# ESP32S31_RADIO register map
Vendor: Espressif; Series: ESP32-S31; File version: 3.52
Registers are 32-bit, read-write, no defined reset value unless marked. A register's access mark holds for its fields unless they carry their own. Offsets are from the block's base; [hi:lo] are bit positions.

## HP_SYS_CLKRST_RADIO — Route-owned high-power system clock/reset words shared by the reviewed Wi-Fi, Bluetooth and IEEE 802.15.4 lifecycles. Unrelated HP_SYS_CLKRST words remain platform-owned.
Base 0x20587000
0x40 MODEM_CTRL0 reset 0x1 — Modem control/register-bus clock gate.
  [0] MODEM_CLK_EN — Modem control/register-bus clock enable.
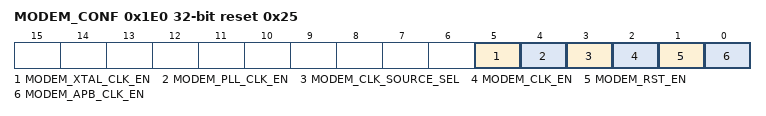
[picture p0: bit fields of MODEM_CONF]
0x1E0 MODEM_CONF reset 0x25 — Modem APB, reset and source-clock configuration.
  [5] MODEM_XTAL_CLK_EN — Modem crystal clock enable.
  [4] MODEM_PLL_CLK_EN — Modem PLL clock enable.
  [3] MODEM_CLK_SOURCE_SEL — Modem source-clock selector.
  [2] MODEM_CLK_EN — Modem source-clock enable.
  [1] MODEM_RST_EN — Modem subsystem reset assertion.
  [0] MODEM_APB_CLK_EN — Modem APB clock enable.

## MODEM_LPCON_SHARED_CLOCK — Role-neutral MODEM_LPCON clock-map, gate and low-power selector registers shared by the exclusive Wi-Fi, Bluetooth and IEEE 802.15.4 routes.
Base 0x2010F000
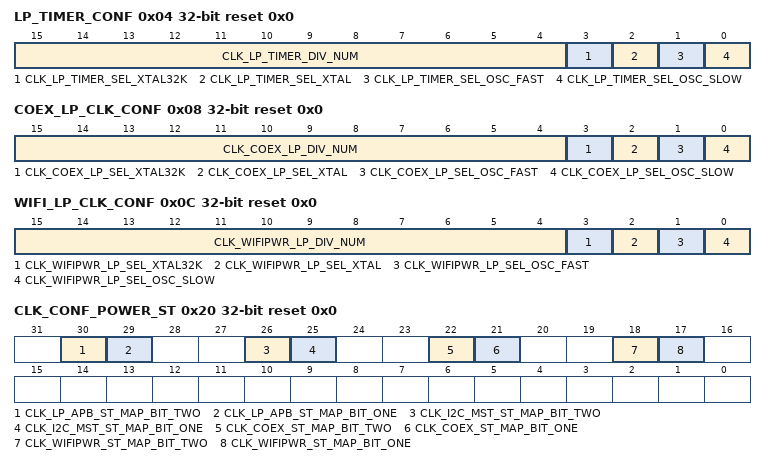
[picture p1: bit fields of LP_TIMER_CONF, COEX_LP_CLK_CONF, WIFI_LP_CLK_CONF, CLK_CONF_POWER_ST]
0x04 LP_TIMER_CONF reset 0x0 — Bluetooth low-power timer source selector and twelve-bit divider.
  [15:4] CLK_LP_TIMER_DIV_NUM — Twelve-bit low-power timer divider image.
  [3] CLK_LP_TIMER_SEL_XTAL32K — Select the 32 kHz crystal clock.
  [2] CLK_LP_TIMER_SEL_XTAL — Select the crystal clock.
  [1] CLK_LP_TIMER_SEL_OSC_FAST — Select the fast oscillator.
  [0] CLK_LP_TIMER_SEL_OSC_SLOW — Select the slow oscillator.
0x08 COEX_LP_CLK_CONF reset 0x0 — Coexistence low-power source selector and twelve-bit divider sampled by the coexistence time conversion.
  [15:4] CLK_COEX_LP_DIV_NUM — Twelve-bit coexistence low-power clock divider image.
  [3] CLK_COEX_LP_SEL_XTAL32K — Select the 32 kHz crystal clock.
  [2] CLK_COEX_LP_SEL_XTAL — Select the crystal clock.
  [1] CLK_COEX_LP_SEL_OSC_FAST — Select the fast oscillator.
  [0] CLK_COEX_LP_SEL_OSC_SLOW — Select the slow oscillator.
0x0C WIFI_LP_CLK_CONF reset 0x0 — Wi-Fi power-domain low-power source selector and twelve-bit divider.
  [15:4] CLK_WIFIPWR_LP_DIV_NUM — Twelve-bit Wi-Fi power-domain low-power divider image.
  [3] CLK_WIFIPWR_LP_SEL_XTAL32K — Select the modem 32 kHz clock chosen by MODEM_32K_CLK_CONF.
  [2] CLK_WIFIPWR_LP_SEL_XTAL — Select the main crystal clock.
  [1] CLK_WIFIPWR_LP_SEL_OSC_FAST — Select the fast oscillator.
  [0] CLK_WIFIPWR_LP_SEL_OSC_SLOW — Select the slow oscillator.
0x14 MODEM_32K_CLK_CONF reset 0x0 — Source of the modem 32 kHz clock selected by the low-power XTAL32K selectors.
  [1:0] CLK_MODEM_32K_SEL — Modem 32 kHz source: zero is the 32 kHz crystal, one the RC32K oscillator and two the external 32 kHz clock.
0x20 CLK_CONF_POWER_ST reset 0x0 — Four shared clock power-state map fields programmed with the reviewed active-state image.
  [30] CLK_LP_APB_ST_MAP_BIT_TWO — Project-assigned name. Bit two of the low-power APB clock state map, set by the reviewed shared active-state initialization.
  [29] CLK_LP_APB_ST_MAP_BIT_ONE — Project-assigned name. Bit one of the low-power APB clock state map, set by the reviewed shared active-state initialization.
  [26] CLK_I2C_MST_ST_MAP_BIT_TWO — Project-assigned name. Bit two of the PHY-I2C-master clock state map, set by the reviewed shared active-state initialization.
  [25] CLK_I2C_MST_ST_MAP_BIT_ONE — Project-assigned name. Bit one of the PHY-I2C-master clock state map, set by the reviewed shared active-state initialization.
  [22] CLK_COEX_ST_MAP_BIT_TWO — Project-assigned name. Bit two of the coexistence clock state map, set by the reviewed shared active-state initialization.
  [21] CLK_COEX_ST_MAP_BIT_ONE — Project-assigned name. Bit one of the coexistence clock state map, set by the reviewed shared active-state initialization.
  [18] CLK_WIFIPWR_ST_MAP_BIT_TWO — Project-assigned name. Bit two of the Wi-Fi-power clock state map, set by the reviewed shared active-state initialization.
  [17] CLK_WIFIPWR_ST_MAP_BIT_ONE — Project-assigned name. Bit one of the Wi-Fi-power clock state map, set by the reviewed shared active-state initialization.
